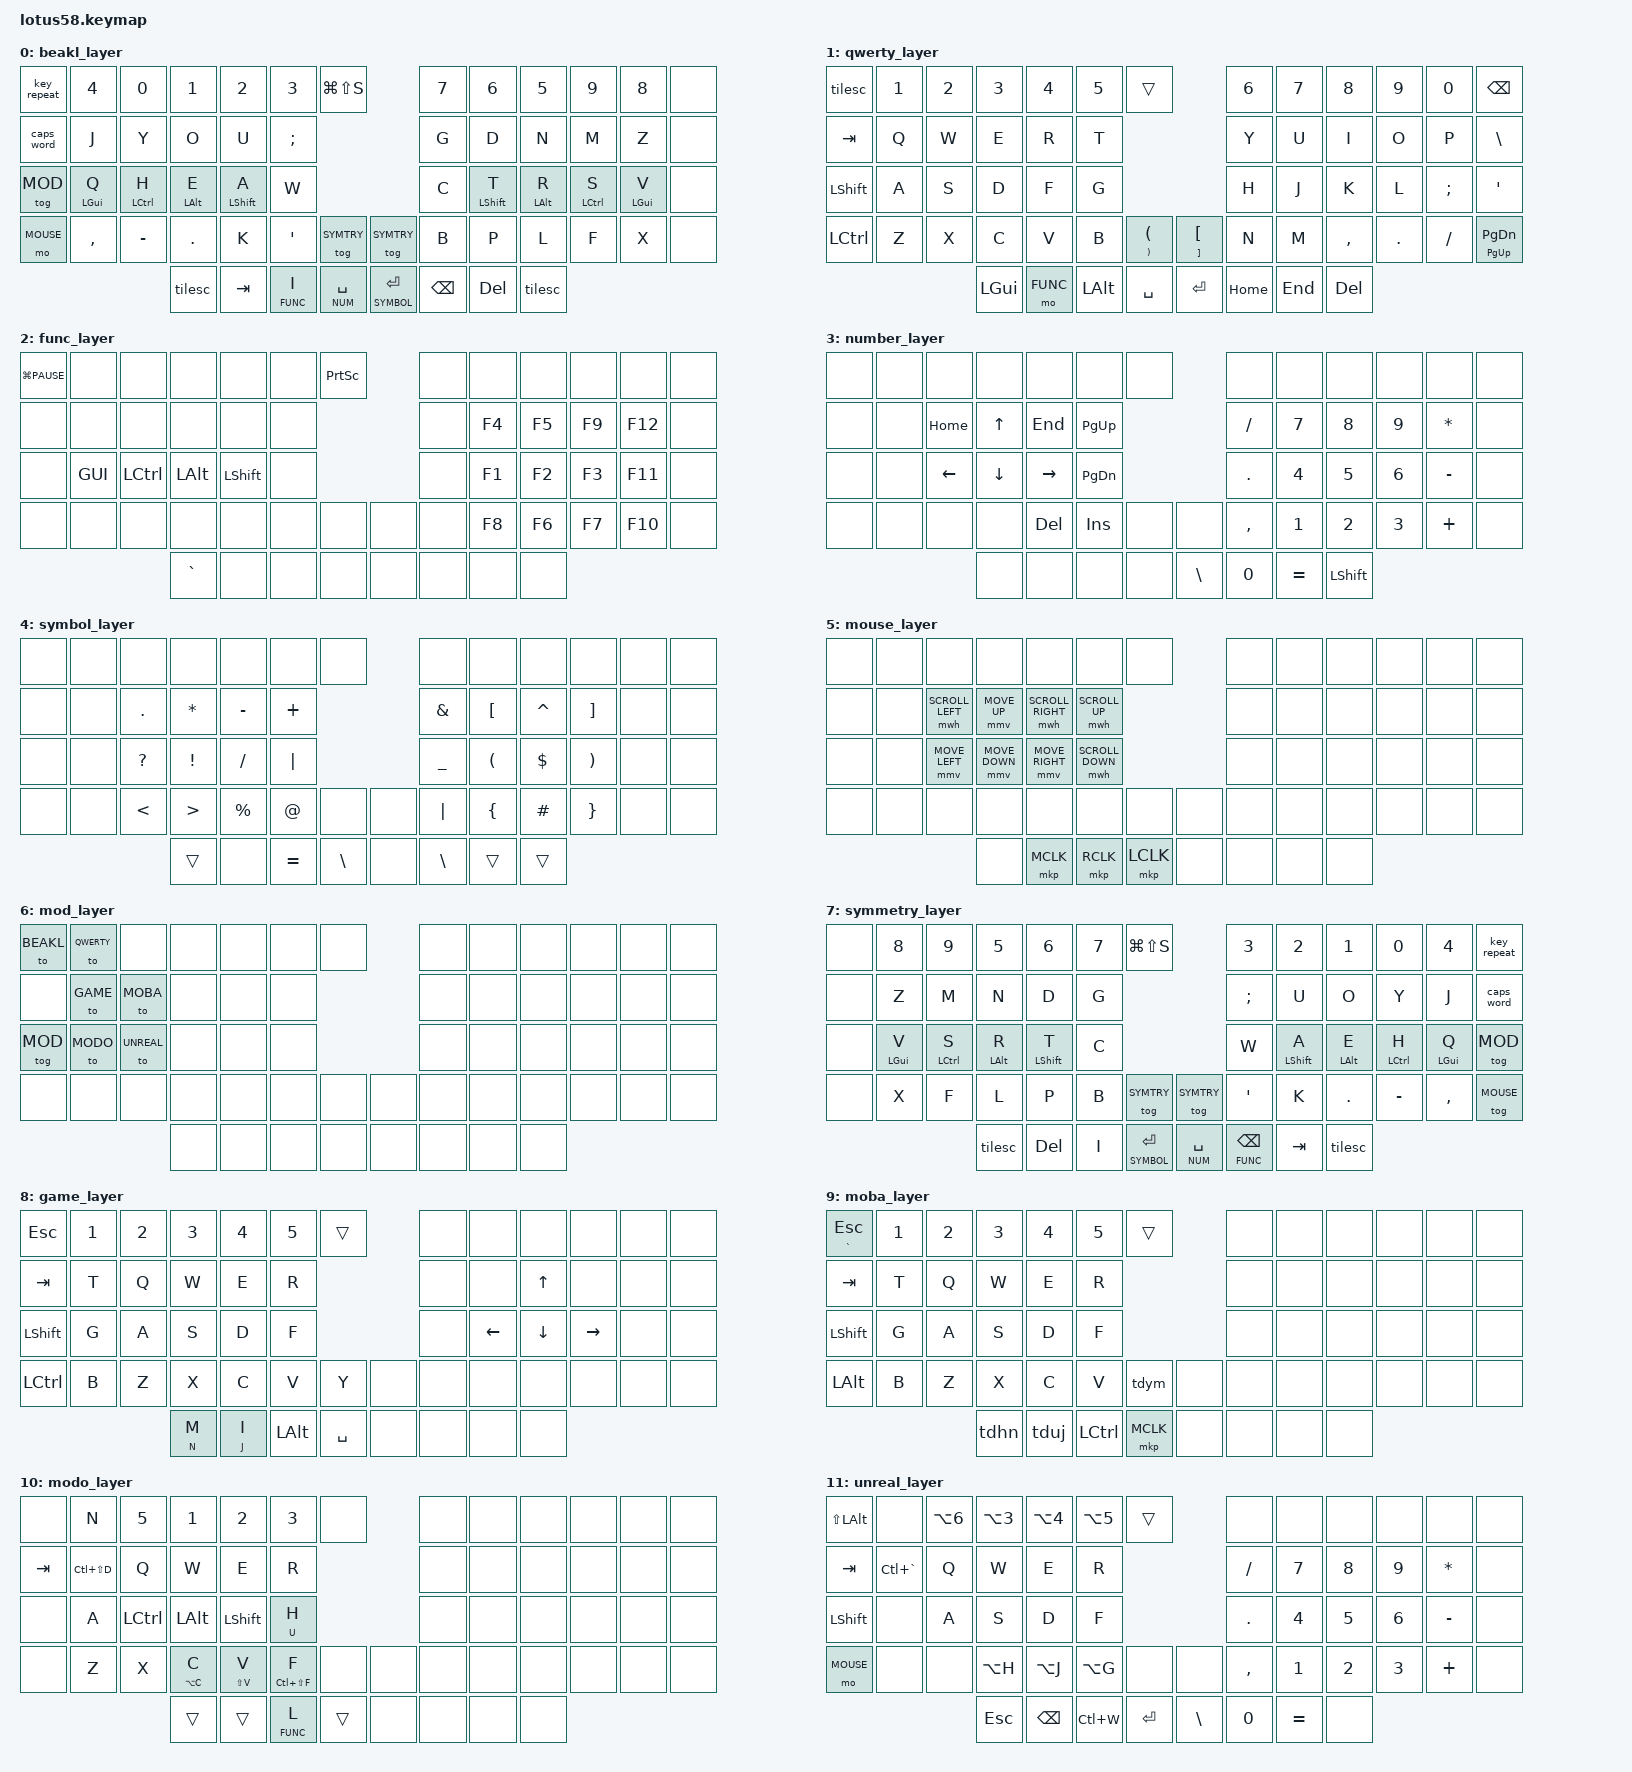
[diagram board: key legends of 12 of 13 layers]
/*
 * Copyright (c) 2020 The ZMK Contributors
 *
 * SPDX-License-Identifier: MIT
 */

#include <behaviors.dtsi>
#include <dt-bindings/zmk/keys.h>
#include <dt-bindings/zmk/bt.h>
#include <dt-bindings/zmk/ext_power.h>
#include <dt-bindings/zmk/mouse.h>

#define ___ &none
#define BEAKL 0
#define QWERTY 1
#define FUNC 2
#define NUM 3
#define SYMBOL 4
#define MOUSE 5
#define MOD 6
#define SYMTRY 7
#define GAME 8
#define MOBA 9
#define MODO 10
#define UNREAL 11
#define PAUSE PAUSE_BREAK
#define MULTIPLY KP_MULTIPLY

&kscan0 {
    debounce-period = <20>;
};

&sk {
    release-after-ms = <200>;
};

&mt {
    tapping-term-ms = <100>;
};

&caps_word {
    continue-list = <COMMA DOT MINUS>;
};

/ {
    behaviors {
        hm: homerow_mods {
            compatible = "zmk,behavior-hold-tap";
            label = "HOMEROW_MODS";
            #binding-cells = <2>;
            tapping-term-ms = <150>;
            quick_tap_ms = <0>;
            flavor = "tap-preferred";
            bindings = <&kp>, <&kp>;
        };

        pm: pinky_mods {
            compatible = "zmk,behavior-hold-tap";
            label = "PINKY_MODS";
            #binding-cells = <2>;
            tapping-term-ms = <200>;
            quick_tap_ms = <0>;
            flavor = "tap-preferred";
            bindings = <&kp>, <&kp>;
        };

        tilesc: mod_morph_tilde_escape {
            compatible = "zmk,behavior-mod-morph";
            label = "TILDE_ESCAPE";
            #binding-cells = <0>;
            bindings = <&kp ESC>, <&kp TILDE>;
            mods = <(MOD_LSFT|MOD_RSFT)>;
        };

        tglt: behavior_togLayer_tap {
            compatible = "zmk,behavior-hold-tap";
            label = "TOGGLE_TAP";
            #binding-cells = <2>;
            flavor = "tap-preferred";
            tapping-term-ms = <200>;
            bindings = <&tog>, <&kp>;
        };

        tdym: tap_dance_ym {            
            compatible = "zmk,behavior-tap-dance";            
            label = "TAP_DANCE_YM";            
            #binding-cells = <0>;            
            tapping-term-ms = <200>;            
            bindings = <&kp Y>, <&kp M>;        
        };

        tdhn: tap_dance_hn {            
            compatible = "zmk,behavior-tap-dance";            
            label = "TAP_DANCE_HN";            
            #binding-cells = <0>;            
            tapping-term-ms = <200>;            
            bindings = <&kp H>, <&kp N>;        
        };

        tduj: tap_dance_uj {            
            compatible = "zmk,behavior-tap-dance";            
            label = "TAP_DANCE_UJ";            
            #binding-cells = <0>;            
            tapping-term-ms = <200>;            
            bindings = <&kp U>, <&kp J>;        
        };
    };

    combos {
              compatible = "zmk,combos";

        combo_undo {
            timeout-ms = <20>;
            key-positions = <38 39>;
            bindings = <&kp LC(Z)>;
        };

        combo_redo {
            timeout-ms = <20>;
            key-positions = <38 40>;
            bindings = <&kp LC(Y)>;
        };

        combo_cut {
            timeout-ms = <20>;
            key-positions = <39 41>;
            bindings = <&kp LC(X)>;
        };

        combo_copy {
            timeout-ms = <20>;
            key-positions = <39 40>;
            bindings = <&kp LC(C)>;
        };

        combo_paste {
            timeout-ms = <20>;
            key-positions = <40 41>;
            bindings = <&kp LC(V)>;
        };

        combo_ret {
            timeout-ms = <20>;
            key-positions = <43 54>;
            bindings = <&kp RET>;
        };

        combo_save {
            timeout-ms = <20>;
            key-positions = <29 30>;
            bindings = <&kp LC(S)>;
        };

        combo_beakl {
            timeout-ms = <20>;
            key-positions = <0 1>;
            bindings = <&to BEAKL>;
        };

        combo_qwerty {
            timeout-ms = <20>;
            key-positions = <0 2>;
            bindings = <&to QWERTY>;
        };

       };

/*    ╭───┬───┬───┬───┬───┬───┬───╮   ╭───┬───┬───┬───┬───┬───┬───╮ */
/*      0   1   2   3   4   5   6           7   8   9   10  11  12  */
/*    ├───┼───┼───┼───┼───┼───┼───┤   │   ├───┼───┼───┼───┼───┼───┤ */
/*      13  14  15  16  17  18              19  20  21  22  23  24  */
/*    ├───┼───┼───┼───┼───┼───┤   │   │   ├───┼───┼───┼───┼───┼───┤ */
/*      25  26  27  28  29  30              31  32  33  34  35  36  */
/*    ├───┼───┼───┼───┼───┼───┼───┤   ├───┼───┼───┼───┼───┼───┼───┤ */
/*      37  38  39  40  41  42  43      44  45  46  47  48  49  50  */
/*    ╰───┴───┴───┼───┼───┼───┼───┤   ├───┼───┼───┼───┼───┴───┴───╯ */
/*                  51  52  53  54      55  56  57  58              */                  
/*                ╰───┴───┴───┴───╯   ╰───┴───┴───┴───╯             */

       keymap {
              compatible = "zmk,keymap";

              beakl_layer {
                     bindings = <
/*    ╭─────────────┬─────────────┬─────────────┬─────────────┬─────────────┬─────────────┬─────────────╮   ╭──────────────┬─────────────┬─────────────┬─────────────┬─────────────┬─────────────┬─────────────╮ */
       &key_repeat   &kp N4        &kp N0        &kp N1        &kp N2        &kp N3        &kp LG(LS(S))                    &kp N7        &kp N6        &kp N5        &kp N9        &kp N8        ___
/*    ├─────────────┼─────────────┼─────────────┼─────────────┼─────────────┼─────────────┼─────────────┤   │              ├─────────────┼─────────────┼─────────────┼─────────────┼─────────────┼─────────────┤ */
       &caps_word    &kp J         &kp Y         &kp O         &kp U         &kp SEMI                                       &kp G         &kp D         &kp N         &kp M         &kp Z         ___
/*    ├─────────────┼─────────────┼─────────────┼─────────────┼─────────────┼─────────────┤             │   │              ├─────────────┼─────────────┼─────────────┼─────────────┼─────────────┼─────────────┤ */
       &tog MOD      &pm LGUI Q    &hm LCTRL H   &hm LALT E    &hm LSHFT A   &kp W                                          &kp C         &hm LSHFT T   &hm LALT R    &hm LCTRL S   &pm LGUI V    ___
/*    ├─────────────┼─────────────┼─────────────┼─────────────┼─────────────┼─────────────┼─────────────┤   ├──────────────┼─────────────┼─────────────┼─────────────┼─────────────┼─────────────┼─────────────┤ */
       &mo  MOUSE    &kp COMMA     &kp MINUS     &kp DOT       &kp K         &kp SQT       &tog SYMTRY       &tog SYMTRY    &kp B         &kp P         &kp L         &kp F         &kp X         ___
/*    ╰─────────────┴─────────────┴─────────────┼─────────────┼─────────────┼─────────────┼─────────────┤   ├──────────────┼─────────────┼─────────────┼─────────────┼─────────────┴─────────────┴─────────────╯ */
                                                 &tilesc       &kp TAB       &lt FUNC I    &lt NUM SPACE     &lt SYMBOL RET &kp BSPC      &kp DEL       &tilesc
/*                                              ╰─────────────┴─────────────┴─────────────┴─────────────╯   ╰──────────────┴─────────────┴─────────────┴─────────────╯                                           */
                     >;

                     sensor-bindings = <&inc_dec_kp C_VOL_UP C_VOL_DN>;
              };

              qwerty_layer {
                     bindings = <
/*    ╭─────────────┬─────────────┬─────────────┬─────────────┬─────────────┬─────────────┬─────────────╮   ╭─────────────┬─────────────┬─────────────┬─────────────┬─────────────┬─────────────┬─────────────╮ */
       &tilesc       &kp N1        &kp N2        &kp N3        &kp N4        &kp N5        &trans                          &kp N6        &kp N7        &kp N8        &kp N9        &kp N0        &kp BSPC
/*    ├─────────────┼─────────────┼─────────────┼─────────────┼─────────────┼─────────────┼─────────────┤   │             ├─────────────┼─────────────┼─────────────┼─────────────┼─────────────┼─────────────┤ */
       &kp TAB       &kp Q         &kp W         &kp E         &kp R         &kp T                                         &kp Y         &kp U         &kp I         &kp O         &kp P         &kp BSLH
/*    ├─────────────┼─────────────┼─────────────┼─────────────┼─────────────┼─────────────┤             │   │             ├─────────────┼─────────────┼─────────────┼─────────────┼─────────────┼─────────────┤ */
       &kp LSHFT     &kp A         &kp S         &kp D         &kp F         &kp G                                         &kp H         &kp J         &kp K         &kp L         &kp SEMI      &kp SQT
/*    ├─────────────┼─────────────┼─────────────┼─────────────┼─────────────┼─────────────┼─────────────┤   ├─────────────┼─────────────┼─────────────┼─────────────┼─────────────┼─────────────┼─────────────┤ */
       &kp LCTRL     &kp Z         &kp X         &kp C         &kp V         &kp B         &mt RPAR LPAR     &mt RBKT LBKT &kp N         &kp M         &kp COMMA     &kp DOT       &kp FSLH      &mt PG_UP PG_DN
/*    ╰─────────────┴─────────────┴─────────────┼─────────────┼─────────────┼─────────────┼─────────────┤   ├─────────────┼─────────────┼─────────────┼─────────────┼─────────────┴─────────────┴─────────────╯ */
                                                 &kp LGUI      &mo FUNC      &kp LALT      &kp SPACE         &kp RET       &kp HOME      &kp END       &kp DEL
/*                                              ╰─────────────┴─────────────┴─────────────┴─────────────╯   ╰─────────────┴─────────────┴─────────────┴─────────────╯                                           */
                     >;

                     sensor-bindings = <&inc_dec_kp C_VOL_UP C_VOL_DN>;
              };

              func_layer {
                     bindings = <
/*    ╭─────────────┬─────────────┬─────────────┬─────────────┬─────────────┬─────────────┬─────────────╮   ╭─────────────┬─────────────┬─────────────┬─────────────┬─────────────┬─────────────┬─────────────╮ */
       &kp LG(PAUSE) ___           ___           ___           ___           ___           &kp PSCRN                       ___           ___           ___           ___           ___           ___
/*    ├─────────────┼─────────────┼─────────────┼─────────────┼─────────────┼─────────────┼─────────────┤   │             ├─────────────┼─────────────┼─────────────┼─────────────┼─────────────┼─────────────┤ */
       ___           ___           ___           ___           ___           ___                                           ___           &kp F4        &kp F5        &kp F9        &kp F12       ___
/*    ├─────────────┼─────────────┼─────────────┼─────────────┼─────────────┼─────────────┤             │   │             ├─────────────┼─────────────┼─────────────┼─────────────┼─────────────┼─────────────┤ */
       ___           &kp GUI       &kp LCTRL     &kp LALT      &kp LSHFT     ___                                           ___           &kp F1        &kp F2        &kp F3        &kp F11       ___
/*    ├─────────────┼─────────────┼─────────────┼─────────────┼─────────────┼─────────────┼─────────────┤   ├─────────────┼─────────────┼─────────────┼─────────────┼─────────────┼─────────────┼─────────────┤ */
       ___           ___           ___           ___           ___           ___           ___               ___           ___           &kp F8        &kp F6        &kp F7        &kp F10       ___
/*    ╰─────────────┴─────────────┴─────────────┼─────────────┼─────────────┼─────────────┼─────────────┤   ├─────────────┼─────────────┼─────────────┼─────────────┼─────────────┴─────────────┴─────────────╯ */
                                                 &kp GRAVE     ___           ___           ___               ___           ___           ___           ___
/*                                              ╰─────────────┴─────────────┴─────────────┴─────────────╯   ╰─────────────┴─────────────┴─────────────┴─────────────╯                                           */
                     >;

                     sensor-bindings = <&inc_dec_kp PG_UP PG_DN>;
              };

              number_layer {
                     bindings = <
/*    ╭─────────────┬─────────────┬─────────────┬─────────────┬─────────────┬─────────────┬─────────────╮   ╭─────────────┬─────────────┬─────────────┬─────────────┬─────────────┬─────────────┬─────────────╮ */
       ___           ___           ___           ___           ___           ___           ___                             ___           ___           ___           ___           ___           ___
/*    ├─────────────┼─────────────┼─────────────┼─────────────┼─────────────┼─────────────┼─────────────┤   │             ├─────────────┼─────────────┼─────────────┼─────────────┼─────────────┼─────────────┤ */
       ___           ___           &kp HOME      &kp UP        &kp END       &kp PG_UP                                     &kp FSLH      &kp N7        &kp N8        &kp N9        &kp STAR      ___
/*    ├─────────────┼─────────────┼─────────────┼─────────────┼─────────────┼─────────────┤             │   │             ├─────────────┼─────────────┼─────────────┼─────────────┼─────────────┼─────────────┤ */
       ___           ___           &kp LEFT      &kp DOWN      &kp RIGHT     &kp PG_DN                                     &kp DOT       &kp N4        &kp N5        &kp N6        &kp MINUS     ___
/*    ├─────────────┼─────────────┼─────────────┼─────────────┼─────────────┼─────────────┼─────────────┤   ├─────────────┼─────────────┼─────────────┼─────────────┼─────────────┼─────────────┼─────────────┤ */
       ___           ___           ___           ___           &kp DEL       &kp INS       ___               ___           &kp COMMA     &kp N1        &kp N2        &kp N3        &kp PLUS      ___
/*    ╰─────────────┴─────────────┴─────────────┼─────────────┼─────────────┼─────────────┼─────────────┤   ├─────────────┼─────────────┼─────────────┼─────────────┼─────────────┴─────────────┴─────────────╯ */
                                                 ___           ___           ___           ___               &kp BSLH      &kp N0        &kp EQUAL     &kp LSHFT
/*                                              ╰─────────────┴─────────────┴─────────────┴─────────────╯   ╰─────────────┴─────────────┴─────────────┴─────────────╯                                           */
                     >;

                     sensor-bindings = <&inc_dec_kp C_VOL_UP C_VOL_DN>;
              };

              symbol_layer {
                     bindings = <
/*    ╭─────────────┬─────────────┬─────────────┬─────────────┬─────────────┬─────────────┬─────────────╮   ╭─────────────┬─────────────┬─────────────┬─────────────┬─────────────┬─────────────┬─────────────╮ */
       ___           ___           ___           ___           ___           ___           ___                             ___           ___           ___           ___           ___           ___
/*    ├─────────────┼─────────────┼─────────────┼─────────────┼─────────────┼─────────────┼─────────────┤   │             ├─────────────┼─────────────┼─────────────┼─────────────┼─────────────┼─────────────┤ */
       ___           ___           &kp DOT       &kp STAR      &kp MINUS     &kp PLUS                                      &kp AMPS      &kp LBKT      &kp CARET     &kp RBKT      ___           ___
/*    ├─────────────┼─────────────┼─────────────┼─────────────┼─────────────┼─────────────┤             │   │             ├─────────────┼─────────────┼─────────────┼─────────────┼─────────────┼─────────────┤ */
       ___           ___           &kp QMARK     &kp EXCL      &kp FSLH      &kp PIPE                                      &kp UNDER     &kp LPAR      &kp DLLR      &kp RPAR      ___           ___
/*    ├─────────────┼─────────────┼─────────────┼─────────────┼─────────────┼─────────────┼─────────────┤   ├─────────────┼─────────────┼─────────────┼─────────────┼─────────────┼─────────────┼─────────────┤ */
       ___           ___           &kp LT        &kp GT        &kp PRCNT     &kp AT        ___               ___           &kp PIPE      &kp LBRC      &kp HASH      &kp RBRC      ___           ___
/*    ╰─────────────┴─────────────┴─────────────┼─────────────┼─────────────┼─────────────┼─────────────┤   ├─────────────┼─────────────┼─────────────┼─────────────┼─────────────┴─────────────┴─────────────╯ */
                                                 &trans        ___           &kp EQUAL     &kp BSLH          ___           &kp BSLH      &trans        &trans
/*                                              ╰─────────────┴─────────────┴─────────────┴─────────────╯   ╰─────────────┴─────────────┴─────────────┴─────────────╯                                           */
                     >;

                     sensor-bindings = <&inc_dec_kp C_VOL_UP C_VOL_DN>;
              };
              
              mouse_layer {
                     bindings = <
/*    ╭─────────────┬─────────────┬─────────────────┬───────────────┬─────────────────┬─────────────────┬─────────────╮   ╭─────────────┬─────────────┬─────────────┬─────────────┬─────────────┬─────────────┬─────────────╮ */
       ___           ___           ___               ___             ___               ___               ___                             ___           ___           ___           ___           ___           ___
/*    ├─────────────┼─────────────┼─────────────────┼───────────────┼─────────────────┼─────────────────┼─────────────┤   │             ├─────────────┼─────────────┼─────────────┼─────────────┼─────────────┼─────────────┤ */
       ___           ___           &mwh SCROLL_LEFT  &mmv MOVE_UP    &mwh SCROLL_RIGHT &mwh SCROLL_UP                                    ___           ___           ___           ___           ___           ___
/*    ├─────────────┼─────────────┼─────────────────┼───────────────┼─────────────────┼─────────────────┤             │   │             ├─────────────┼─────────────┼─────────────┼─────────────┼─────────────┼─────────────┤ */
       ___           ___           &mmv MOVE_LEFT    &mmv MOVE_DOWN  &mmv MOVE_RIGHT   &mwh SCROLL_DOWN                                  ___           ___           ___           ___           ___           ___
/*    ├─────────────┼─────────────┼─────────────────┼───────────────┼─────────────────┼─────────────────┼─────────────┤   ├─────────────┼─────────────┼─────────────┼─────────────┼─────────────┼─────────────┼─────────────┤ */
       ___           ___           ___               ___             ___               ___               ___               ___           ___           ___           ___           ___           ___           ___
/*    ╰─────────────┴─────────────┴─────────────────┼───────────────┼─────────────────┼─────────────────┼─────────────┤   ├─────────────┼─────────────┼─────────────┼─────────────┼─────────────┴─────────────┴─────────────╯ */
                                                     ___             &mkp MCLK         &mkp RCLK         &mkp LCLK         ___           ___           ___           ___
/*                                                  ╰───────────────┴─────────────────┴─────────────────┴─────────────╯   ╰─────────────┴─────────────┴─────────────┴─────────────╯                                           */
                     >;

                     sensor-bindings = <&inc_dec_kp C_VOL_UP C_VOL_DN>;
              };

              mod_layer {
                     bindings = <
/*    ╭─────────────┬─────────────┬─────────────┬─────────────┬─────────────┬─────────────┬─────────────╮   ╭─────────────┬─────────────┬─────────────┬─────────────┬─────────────┬─────────────┬─────────────╮ */
       &to BEAKL     &to QWERTY    ___           ___           ___           ___           ___                             ___           ___           ___           ___           ___           ___
/*    ├─────────────┼─────────────┼─────────────┼─────────────┼─────────────┼─────────────┼─────────────┤   │             ├─────────────┼─────────────┼─────────────┼─────────────┼─────────────┼─────────────┤ */
       ___           &to GAME      &to MOBA      ___           ___           ___                                           ___           ___           ___           ___           ___           ___
/*    ├─────────────┼─────────────┼─────────────┼─────────────┼─────────────┼─────────────┤             │   │             ├─────────────┼─────────────┼─────────────┼─────────────┼─────────────┼─────────────┤ */
       &tog MOD      &to MODO      &to UNREAL    ___           ___           ___                                           ___           ___           ___           ___           ___           ___
/*    ├─────────────┼─────────────┼─────────────┼─────────────┼─────────────┼─────────────┼─────────────┤   ├─────────────┼─────────────┼─────────────┼─────────────┼─────────────┼─────────────┼─────────────┤ */
       ___           ___           ___           ___           ___           ___           ___               ___           ___           ___           ___           ___           ___           ___
/*    ╰─────────────┴─────────────┴─────────────┼─────────────┼─────────────┼─────────────┼─────────────┤   ├─────────────┼─────────────┼─────────────┼─────────────┼─────────────┴─────────────┴─────────────╯ */
                                                 ___           ___           ___           ___               ___           ___           ___           ___
/*                                              ╰─────────────┴─────────────┴─────────────┴─────────────╯   ╰─────────────┴─────────────┴─────────────┴─────────────╯                                           */
                     >;

                     sensor-bindings = <&inc_dec_kp C_VOL_UP C_VOL_DN>;
              };

              symmetry_layer {
                     bindings = <
/*    ╭─────────────┬─────────────┬─────────────┬─────────────┬─────────────┬─────────────┬─────────────╮   ╭─────────────┬─────────────┬─────────────┬─────────────┬─────────────┬─────────────┬─────────────╮ */
       ___           &kp N8        &kp N9        &kp N5        &kp N6        &kp N7        &kp LG(LS(S))                   &kp N3        &kp N2        &kp N1        &kp N0        &kp N4        &key_repeat
/*    ├─────────────┼─────────────┼─────────────┼─────────────┼─────────────┼─────────────┼─────────────┤   │             ├─────────────┼─────────────┼─────────────┼─────────────┼─────────────┼─────────────┤ */
       ___           &kp Z         &kp M         &kp N         &kp D         &kp G                                         &kp SEMI      &kp U         &kp O         &kp Y          &kp J        &caps_word
/*    ├─────────────┼─────────────┼─────────────┼─────────────┼─────────────┼─────────────┤             │   │             ├─────────────┼─────────────┼─────────────┼─────────────┼─────────────┼─────────────┤ */
       ___           &pm LGUI V    &hm LCTRL S   &hm LALT R    &hm LSHFT T   &kp C                                         &kp W         &hm LSHFT A   &hm LALT E    &hm LCTRL H   &pm LGUI Q    &tog MOD
/*    ├─────────────┼─────────────┼─────────────┼─────────────┼─────────────┼─────────────┼─────────────┤   ├─────────────┼─────────────┼─────────────┼─────────────┼─────────────┼─────────────┼─────────────┤ */
       ___           &kp X         &kp F         &kp L         &kp P         &kp B         &tog SYMTRY       &tog SYMTRY   &kp SQT       &kp K         &kp DOT       &kp MINUS     &kp COMMA     &tog MOUSE
/*    ╰─────────────┴─────────────┴─────────────┼─────────────┼─────────────┼─────────────┼─────────────┤   ├─────────────┼─────────────┼─────────────┼─────────────┼─────────────┴─────────────┴─────────────╯ */
                                                 &tilesc       &kp DEL       &kp I         &lt SYMBOL RET    &lt NUM SPACE &lt FUNC BSPC &kp TAB       &tilesc       
/*                                              ╰─────────────┴─────────────┴─────────────┴─────────────╯   ╰─────────────┴─────────────┴─────────────┴─────────────╯                                           */
                     >;

                     sensor-bindings = <&inc_dec_kp C_VOL_UP C_VOL_DN>;
              };
              
              game_layer {
                     bindings = <
/*    ╭─────────────┬─────────────┬─────────────┬─────────────┬─────────────┬─────────────┬─────────────╮   ╭─────────────┬─────────────┬─────────────┬─────────────┬─────────────┬─────────────┬─────────────╮ */
       &kp ESC       &kp N1        &kp N2        &kp N3        &kp N4        &kp N5        &trans                          ___           ___           ___           ___           ___           ___
/*    ├─────────────┼─────────────┼─────────────┼─────────────┼─────────────┼─────────────┼─────────────┤   │             ├─────────────┼─────────────┼─────────────┼─────────────┼─────────────┼─────────────┤ */
       &kp TAB       &kp T         &kp Q         &kp W         &kp E         &kp R                                         ___           ___           &kp UP        ___           ___           ___
/*    ├─────────────┼─────────────┼─────────────┼─────────────┼─────────────┼─────────────┤             │   │             ├─────────────┼─────────────┼─────────────┼─────────────┼─────────────┼─────────────┤ */
       &kp LSHFT     &kp G         &kp A         &kp S         &kp D         &kp F                                         ___           &kp LEFT      &kp DOWN      &kp RIGHT     ___           ___
/*    ├─────────────┼─────────────┼─────────────┼─────────────┼─────────────┼─────────────┼─────────────┤   ├─────────────┼─────────────┼─────────────┼─────────────┼─────────────┼─────────────┼─────────────┤ */
       &kp LCTRL     &kp B         &kp Z         &kp X         &kp C         &kp V         &kp Y             ___           ___           ___           ___           ___           ___           ___
/*    ╰─────────────┴─────────────┴─────────────┼─────────────┼─────────────┼─────────────┼─────────────┤   ├─────────────┼─────────────┼─────────────┼─────────────┼─────────────┴─────────────┴─────────────╯ */
                                                 &mt N M       &mt J I       &kp LALT      &kp SPACE         ___           ___           ___           ___
/*                                              ╰─────────────┴─────────────┴─────────────┴─────────────╯   ╰─────────────┴─────────────┴─────────────┴─────────────╯                                           */
                     >;

                     sensor-bindings = <&inc_dec_kp PG_UP PG_DN>;
              };

              moba_layer {
                     bindings = <
/*    ╭─────────────┬─────────────┬─────────────┬─────────────┬─────────────┬─────────────┬─────────────╮   ╭─────────────┬─────────────┬─────────────┬─────────────┬─────────────┬─────────────┬─────────────╮ */
       &mt GRAVE ESC &kp N1        &kp N2        &kp N3        &kp N4        &kp N5        &trans                          ___           ___           ___           ___           ___           ___
/*    ├─────────────┼─────────────┼─────────────┼─────────────┼─────────────┼─────────────┼─────────────┤   │             ├─────────────┼─────────────┼─────────────┼─────────────┼─────────────┼─────────────┤ */
       &kp TAB       &kp T         &kp Q         &kp W         &kp E         &kp R                                         ___           ___           ___           ___           ___           ___
/*    ├─────────────┼─────────────┼─────────────┼─────────────┼─────────────┼─────────────┤             │   │             ├─────────────┼─────────────┼─────────────┼─────────────┼─────────────┼─────────────┤ */
       &kp LSHFT     &kp G         &kp A         &kp S         &kp D         &kp F                                         ___           ___           ___           ___           ___           ___
/*    ├─────────────┼─────────────┼─────────────┼─────────────┼─────────────┼─────────────┼─────────────┤   ├─────────────┼─────────────┼─────────────┼─────────────┼─────────────┼─────────────┼─────────────┤ */
       &kp LALT      &kp B         &kp Z         &kp X         &kp C         &kp V         &tdym             ___           ___           ___           ___           ___           ___           ___
/*    ╰─────────────┴─────────────┴─────────────┼─────────────┼─────────────┼─────────────┼─────────────┤   ├─────────────┼─────────────┼─────────────┼─────────────┼─────────────┴─────────────┴─────────────╯ */
                                                 &tdhn         &tduj         &kp LCTRL     &mkp MCLK         ___           ___           ___           ___
/*                                              ╰─────────────┴─────────────┴─────────────┴─────────────╯   ╰─────────────┴─────────────┴─────────────┴─────────────╯                                           */
                     >;

                     sensor-bindings = <&inc_dec_kp C_VOL_UP C_VOL_DN>;
              };

              modo_layer {
                     bindings = <
/*    ╭─────────────┬─────────────┬─────────────┬─────────────┬─────────────┬────────────────┬─────────────╮   ╭─────────────┬─────────────┬─────────────┬─────────────┬─────────────┬─────────────┬─────────────╮ */
       ___           &kp N         &kp N5        &kp N1        &kp N2        &kp N3           ___                             ___           ___           ___           ___           ___           ___
/*    ├─────────────┼─────────────┼─────────────┼─────────────┼─────────────┼────────────────┼─────────────┤   │             ├─────────────┼─────────────┼─────────────┼─────────────┼─────────────┼─────────────┤ */
       &kp TAB       &kp LC(LS(D)) &kp Q         &kp W         &kp E         &kp R                                            ___           ___           ___           ___           ___           ___
/*    ├─────────────┼─────────────┼─────────────┼─────────────┼─────────────┼────────────────┤             │   │             ├─────────────┼─────────────┼─────────────┼─────────────┼─────────────┼─────────────┤ */
       ___           &kp A         &kp LCTRL     &kp LALT      &kp LSHFT     &mt U H                                          ___           ___           ___           ___           ___           ___
/*    ├─────────────┼─────────────┼─────────────┼─────────────┼─────────────┼────────────────┼─────────────┤   ├─────────────┼─────────────┼─────────────┼─────────────┼─────────────┼─────────────┼─────────────┤ */
       ___           &kp Z         &kp X         &mt LA(C) C   &mt LS(V) V   &mt LC(LS(F)) F  ___               ___           ___           ___           ___           ___           ___           ___
/*    ╰─────────────┴─────────────┴─────────────┼─────────────┼─────────────┼────────────────┼─────────────┤   ├─────────────┼─────────────┼─────────────┼─────────────┼─────────────┴─────────────┴─────────────╯ */
                                                 &trans        &trans        &lt FUNC L       &trans            ___           ___           ___           ___
/*                                              ╰─────────────┴─────────────┴────────────────┴─────────────╯   ╰─────────────┴─────────────┴─────────────┴─────────────╯                                           */
                     >;

                     sensor-bindings = <&inc_dec_kp C_VOL_UP C_VOL_DN>;
              };

              unreal_layer {
                     bindings = <
/*    ╭─────────────┬─────────────┬─────────────┬─────────────┬─────────────┬─────────────┬─────────────╮   ╭─────────────┬─────────────┬─────────────┬─────────────┬─────────────┬─────────────┬─────────────╮ */
       &kp LS(LALT)  ___           &kp LA(N6)    &kp LA(N3)    &kp LA(N4)    &kp LA(N5)    &trans                          ___           ___           ___           ___           ___           ___
/*    ├─────────────┼─────────────┼─────────────┼─────────────┼─────────────┼─────────────┼─────────────┤   │             ├─────────────┼─────────────┼─────────────┼─────────────┼─────────────┼─────────────┤ */
       &kp TAB       &kp LC(GRAVE) &kp Q         &kp W         &kp E         &kp R                                         &kp FSLH      &kp N7        &kp N8        &kp N9        &kp STAR      ___
/*    ├─────────────┼─────────────┼─────────────┼─────────────┼─────────────┼─────────────┤             │   │             ├─────────────┼─────────────┼─────────────┼─────────────┼─────────────┼─────────────┤ */
       &kp LSHFT     ___           &kp A         &kp S         &kp D         &kp F                                         &kp DOT       &kp N4        &kp N5        &kp N6        &kp MINUS     ___
/*    ├─────────────┼─────────────┼─────────────┼─────────────┼─────────────┼─────────────┼─────────────┤   ├─────────────┼─────────────┼─────────────┼─────────────┼─────────────┼─────────────┼─────────────┤ */
       &mo MOUSE     ___           ___           &kp LA(H)     &kp LA(J)     &kp LA(G)     ___               ___           &kp COMMA     &kp N1        &kp N2        &kp N3        &kp PLUS      ___
/*    ╰─────────────┴─────────────┴─────────────┼─────────────┼─────────────┼─────────────┼─────────────┤   ├─────────────┼─────────────┼─────────────┼─────────────┼─────────────┴─────────────┴─────────────╯ */
                                                 &kp ESC       &kp BSPC      &kp LC(W)     &kp RET           &kp BSLH      &kp N0        &kp EQUAL     ___
/*                                              ╰─────────────┴─────────────┴─────────────┴─────────────╯   ╰─────────────┴─────────────┴─────────────┴─────────────╯                                           */
                     >;

                     sensor-bindings = <&inc_dec_kp C_VOL_UP C_VOL_DN>;
              };

              blank_layer {
                     bindings = <
/*    ╭─────────────┬─────────────┬─────────────┬─────────────┬─────────────┬─────────────┬─────────────╮   ╭─────────────┬─────────────┬─────────────┬─────────────┬─────────────┬─────────────┬─────────────╮ */
       ___           ___           ___           ___           ___           ___           ___                             ___           ___           ___           ___           ___           ___
/*    ├─────────────┼─────────────┼─────────────┼─────────────┼─────────────┼─────────────┼─────────────┤   │             ├─────────────┼─────────────┼─────────────┼─────────────┼─────────────┼─────────────┤ */
       ___           &kp Q         ___           ___           ___           ___                                           ___           ___           ___           ___           ___           ___
/*    ├─────────────┼─────────────┼─────────────┼─────────────┼─────────────┼─────────────┤             │   │             ├─────────────┼─────────────┼─────────────┼─────────────┼─────────────┼─────────────┤ */
       ___           ___           ___           ___           ___           ___                                           ___           ___           ___           ___           ___           ___
/*    ├─────────────┼─────────────┼─────────────┼─────────────┼─────────────┼─────────────┼─────────────┤   ├─────────────┼─────────────┼─────────────┼─────────────┼─────────────┼─────────────┼─────────────┤ */
       ___           ___           ___           ___           ___           ___           ___               ___           ___           ___           ___           ___           ___           ___
/*    ╰─────────────┴─────────────┴─────────────┼─────────────┼─────────────┼─────────────┼─────────────┤   ├─────────────┼─────────────┼─────────────┼─────────────┼─────────────┴─────────────┴─────────────╯ */
                                                 ___           ___           ___           ___               ___           ___           ___           ___
/*                                              ╰─────────────┴─────────────┴─────────────┴─────────────╯   ╰─────────────┴─────────────┴─────────────┴─────────────╯                                           */
                     >;

                     sensor-bindings = <&inc_dec_kp C_VOL_UP C_VOL_DN>;
              };
       };
};
